# AT32A403A register map
Vendor: Keil; Series: AT32A403A; File version: 1.0
CPU: CM4 r0p1, little endian, no MPU, FPU, 4 interrupt priority bits
Registers are 32-bit, read-write, reset 0x0 unless marked. A register's access mark holds for its fields unless they carry their own. Offsets are from the block's base; [hi:lo] are bit positions; {n}, {i} and the like mark numbered series.

## SDIO1 — Secure digital input/output interface
Base 0x40018000
Same registers: SDIO2 0x40023400
0x00 PWRCTRL — Bits 1:0 = PWRCTRL: Power supply control bits
  [1:0] PS — Power switch
    0=PoweredOff (Power off, card clock stopped); 3=PoweredOn (Power on, card clock started)
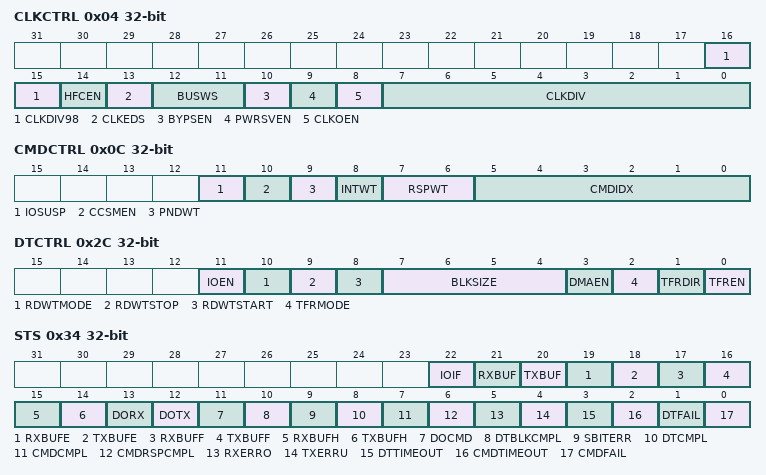
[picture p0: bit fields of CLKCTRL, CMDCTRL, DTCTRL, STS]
0x04 CLKCTRL — SD clock control register (SDIO_CLKCTRL)
  [16:15] CLKDIV98 — 8-9 bits of CLKDIV. SDIO_CK = SDIOCLK / (CLKDIV + 2)
  [14] HFCEN — Hardware flow control enable
    0=Disabled (Hardware flow control disabled); 1=Enabled (Hardware flow control enabled)
  [13] CLKEDS — SDIO_CK edge selection bit
    0=Rising (SDIO_CK is generated on the rising edge of the SDIOCLK); 1=Falling (SDIO_CK is generated on the falling edge of the SDIOCLK)
  [12:11] BUSWS — Bus width selection
    0=OneBit (1-bit data transfer); 1=FourBit (4-bit data transfer); 2=EightBit (8-bit data transfer)
  [10] BYPSEN — Clock divider bypass enable bit
    0=NotBypassed (SDIO_CK output signal is driven by the SDIOCLK that is divided according to the CLKDIV value); 1=Bypassed (SDIO_CK output signal is directly driven by the SDIOCLK)
  [9] PWRSVEN — Power saving mode enable
    0=Normal (SDIO_CK is always output); 1=PowerSaving (SDIO_CK is only output when the bus is active)
  [8] CLKOEN — Clock output enable
    0=Disabled (SDIO_CK output signal is disabled); 1=Enabled (SDIO_CK output signal is enabled)
  [7:0] CLKDIV — 0-7 bits of CLKDIV. SDIO_CK = SDIOCLK / (CLKDIV + 2)
0x08 ARGU — Bits 31:0 = : Command argument
  [31:0] ARGU — Command argument
0x0C CMDCTRL — SDIO command control register (SDIO_CMDCTRL)
  [11] IOSUSP — SD I/O suspend command
    0=NotSuspended (SD I/O suspend command disabled); 1=Suspended (Next command is SD I/O suspend command)
  [10] CCSMEN — Command channel state machine
    on read: 0=Disabled (Command channel state machine disabled); 1=Enabled (Command channel state machine enabled) | on write: 0=Disable command channel state machine; 1=Enable command channel state machine
  [9] PNDWT — CCSM wait for end of transfer
    0=Disabled (Wait for transfer before sending command disabled); 1=Enabled (Wait for transfer before sending command enabled)
  [8] INTWT — CCSM wait for interrupt
    0=Disabled (Wait for interrupt before sending command disabled); 1=Enabled (Wait for interrupt before sending command enabled, CCSM command timeout disabled)
  [7:6] RSPWT — Wait for response
    1=ShortResponse; 3=LongResponse; other=NoResponse
  [5:0] CMDIDX
0x10 RSPCMD ro — SDIO command register
  [5:0] RSPCMD
{0x10+4i} RSP{i} ro (i=1..4) — Bits 31:0 = CARDSTATUS{i}
  [31:0] CARDSTS{i} — CARDSTATUS{i}
0x24 DTTMR — Bits 31:0 = TIMEOUT: Data timeout period
  [31:0] TIMEOUT — Data timeout period
0x28 DTLEN — Bits 24:0 = DATALENGTH: Data length value
  [24:0] DTLEN — Data length value
0x2C DTCTRL — SDIO data control register (SDIO_DCTRL)
  [11] IOEN — SD I/O function enable
    0=Disabled (SD I/O disabled); 1=Enabled (SD I/O enabled)
  [10] RDWTMODE — RWMOD
    0=SDIO_D2 controls data read wait; 1=SDIO_CK controls data read wait
  [9] RDWTSTOP — PWSTOP
    0=InProgress (Read wait is in progress if the RDWTSTART is set.); 1=Stopped (Read wait is stopped if the RDWTSTART is set.)
  [8] RDWTSTART — PWSTART
    0=Disabled (Read wait disabled); 1=Enabled (Read wait enabled)
  [7:4] BLKSIZE — DBLOCKSIZE
    0=B1 (1-byte data transfer); 1=B2 (2-byte data transfer); 2=B4 (4-byte data transfer); 3=B8 (8-byte data transfer); 4=B16 (16-byte data transfer); 5=B32 (32-byte data transfer); 6=B64 (64-byte data transfer); 7=B128 (128-byte data transfer); 8=B256 (256-byte data transfer); 9=B512 (512-byte data transfer); 10=B1024 (1024-byte data transfer); 11=B2048 (2048-byte data transfer); 12=B4096 (4096-byte data transfer); 13=B8192 (8192-byte data transfer); 14=B16384 (16384-byte data transfer)
  [3] DMAEN
    0=Disabled (DMA disabled); 1=Enabled (DMA enabled)
  [2] TFRMODE — DTMODE
    0=Block data transfer mode; 1=Stream data transfer mode
  [1] TFRDIR — DTDIR
    0=ToCard (Data transfer direction: to card); 1=FromCard (Data transfer direction: from card)
  [0] TFREN — DTEN
    0=Disabled (Data transfer disabled); 1=Enabled (Data transfer enabled. DCSM enters the Wait_S or Wait_R state)
0x30 DTCNT ro — Bits 24:0 = DATACOUNT: Data count value
  [24:0] CNT range 0..131071 — Data count value
0x34 STS ro — SDIO status register (SDIO_STS)
  [all] fields
    0=NotSet (Flag is not set); 1=Set (Flag is set)
  [22] IOIF — SD I/O interrupt
  [21] RXBUF — Rx data vaild
  [20] TXBUF — Tx data vaild
  [19] RXBUFE — Rx buffer empty
  [18] TXBUFE — Tx buffer empty
  [17] RXBUFF — Rx buffer full
  [16] TXBUFF — Tx buffer full
  [15] RXBUFH — Rx buffer half empty
  [14] TXBUFH — Tx buffer half empty
  [13] DORX — Data receive in progress
  [12] DOTX — Data transmit in progress
  [11] DOCMD — Command transfer in progress
  [10] DTBLKCMPL — Data block sent
  [9] SBITERR — Start bit error
  [8] DTCMPL — Data sent
  [7] CMDCMPL — Command sent
  [6] CMDRSPCMPL — Command response complete
  [5] RXERRO — Rx over run error
  [4] TXERRU — Tx under run error
  [3] DTTIMEOUT — Data timeout
  [2] CMDTIMEOUT — Command timeout
  [1] DTFAIL — Data crc fail
  [0] CMDFAIL — Command crc fail
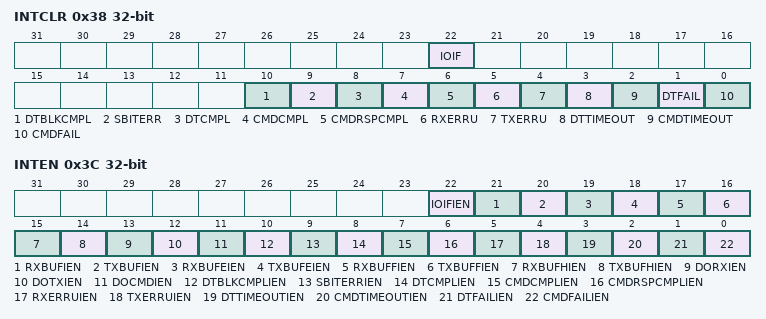
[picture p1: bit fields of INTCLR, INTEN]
0x38 INTCLR — SDIO interrupt clear register (SDIO_INTCLR)
  [all] fields
    1=Clear the corresponding flag in STS
  [22] IOIF — SD I/O interrupt flag clear
  [10] DTBLKCMPL — Data block sent clear
  [9] SBITERR — Start bit error flag clear
  [8] DTCMPL — Data sent flag clear
  [7] CMDCMPL — Command sent flag clear
  [6] CMDRSPCMPL — Command response complete flag clear
  [5] RXERRU — Rx over run error flag clear
  [4] TXERRU — Tx under run error flag clear
  [3] DTTIMEOUT — Data timeout flag clear
  [2] CMDTIMEOUT — Command timeout flag clear
  [1] DTFAIL — Data crc fail flag clear
  [0] CMDFAIL — Command crc fail flag clear
0x3C INTEN — SDIO interrupt enable register (SDIO_INTEN)
  [all] fields
    0=Disabled (Interrupt disabled); 1=Enabled (Interrupt enabled)
  [22] IOIFIEN — SD I/O interrupt enable
  [21] RXBUFIEN — Rx buffer data vaild interrupt enable
  [20] TXBUFIEN — Tx buffer data vaild interrupt enable
  [19] RXBUFEIEN — Rx buffer empty interrupt enable
  [18] TXBUFEIEN — Tx buffer empty interrupt enable
  [17] RXBUFFIEN — Rx buffer full interrupt enable
  [16] TXBUFFIEN — Tx buffer full interrupt enable
  [15] RXBUFHIEN — Rx buffer half empty interrupt enable
  [14] TXBUFHIEN — Tx buffer half empty interrupt enable
  [13] DORXIEN — Data receive acting interrupt enable
  [12] DOTXIEN — Data transmit acting interrupt enable
  [11] DOCMDIEN — Command acting interrupt enable
  [10] DTBLKCMPLIEN — Data block sent complete interrupt enable
  [9] SBITERRIEN — Start bit error interrupt enable
  [8] DTCMPLIEN — Data sent complete interrupt enable
  [7] CMDCMPLIEN — Command sent complete interrupt enable
  [6] CMDRSPCMPLIEN — Command response complete interrupt enable
  [5] RXERRUIEN — Rx over run interrupt enable
  [4] TXERRUIEN — Tx under run interrupt enable
  [3] DTTIMEOUTIEN — Data timeout interrupt enable
  [2] CMDTIMEOUTIEN — Command timeout interrupt enable
  [1] DTFAILIEN — Data crc fail interrupt enable
  [0] CMDFAILIEN — Command crc fail interrupt enable
0x48 BUFCNT ro — Bits 23:0 = BUFCOUNT: Remaining number of words to be written to or read from the FIFO
  [23:0] CNT range 0..65535 — FIF0COUNT
0x80 BUF — bits 31:0 = Buffer Data: Receive and transmit buffer data
  [31:0] DT — Buffer data
